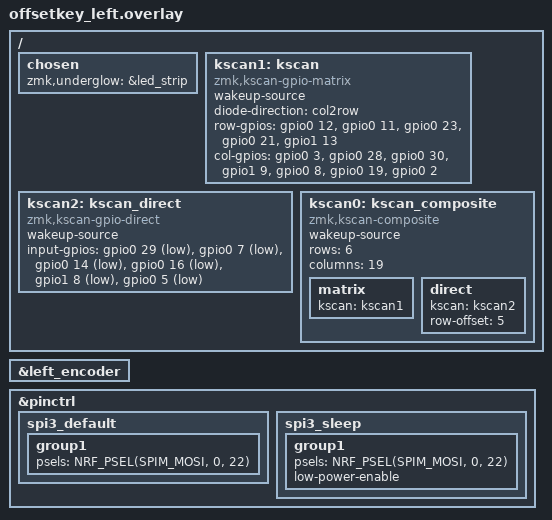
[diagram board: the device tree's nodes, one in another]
/*
 * Copyright (c) 2020 ZMK Contributors
 *
 * SPDX-License-Identifier: MIT
 */
#include <dt-bindings/led/led.h>
#include "offsetkey.dtsi"
/ {
	chosen {
        zmk,underglow = &led_strip;
    };

    kscan1: kscan {
        wakeup-source;
        diode-direction = "col2row";
        compatible = "zmk,kscan-gpio-matrix";
        row-gpios
            = <&gpio0 12 (GPIO_ACTIVE_HIGH | GPIO_PULL_DOWN)>
            , <&gpio0 11 (GPIO_ACTIVE_HIGH | GPIO_PULL_DOWN)>
            , <&gpio0 23 (GPIO_ACTIVE_HIGH | GPIO_PULL_DOWN)>
            , <&gpio0 21 (GPIO_ACTIVE_HIGH | GPIO_PULL_DOWN)>
            , <&gpio1 13 (GPIO_ACTIVE_HIGH | GPIO_PULL_DOWN)>
            ;
        col-gpios
            = <&gpio0 3  GPIO_ACTIVE_HIGH>
            , <&gpio0 28  GPIO_ACTIVE_HIGH>
            , <&gpio0 30  GPIO_ACTIVE_HIGH>
            , <&gpio1 9  GPIO_ACTIVE_HIGH>
            , <&gpio0 8  GPIO_ACTIVE_HIGH>
            , <&gpio0 19  GPIO_ACTIVE_HIGH>
            , <&gpio0 2  GPIO_ACTIVE_HIGH>
            ;
    };

    kscan2: kscan_direct {
        compatible = "zmk,kscan-gpio-direct";
        wakeup-source;
        input-gpios
            = <&gpio0 29 (GPIO_ACTIVE_LOW | GPIO_PULL_UP)>
            , <&gpio0 7 (GPIO_ACTIVE_LOW | GPIO_PULL_UP)>
            , <&gpio0 14 (GPIO_ACTIVE_LOW | GPIO_PULL_UP)>
            , <&gpio0 16 (GPIO_ACTIVE_LOW | GPIO_PULL_UP)>
            , <&gpio1 8 (GPIO_ACTIVE_LOW | GPIO_PULL_UP)>
            , <&gpio0 5 (GPIO_ACTIVE_LOW | GPIO_PULL_UP)>
            ;
    };

    kscan0: kscan_composite {
        compatible = "zmk,kscan-composite";
  wakeup-source;
        rows = <6>;
        columns = <19>;

        // Include the matrix driver
        matrix {
            kscan = <&kscan1>;
        };

        // Include the direct GPIO driver...
        direct {
            kscan = <&kscan2>;
            row-offset = <5>;
        };
    };
};

&left_encoder {
    status = "okay";
};

&pinctrl {

    spi3_default: spi3_default {
        group1 {
            psels = <NRF_PSEL(SPIM_MOSI, 0, 22)>; // WS2812_VEXT_DATA
        };
    };

    spi3_sleep: spi3_sleep {
        group1 {
            psels = <NRF_PSEL(SPIM_MOSI, 0, 22)>;
            low-power-enable;
        };
    };
};

#include "rgb.dtsi"
